AUTOSAR XML (schema 4-2-2)
package /ASW_CORE0
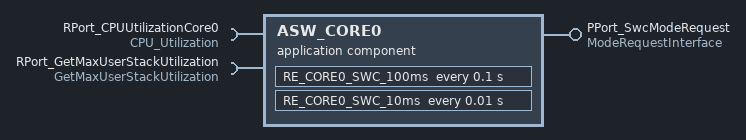
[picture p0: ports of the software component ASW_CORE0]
  application sw component type ASW_CORE0
    require port RPort_CPUUtilizationCore0: required-interface=CPU_Utilization
    provide port PPort_SwcModeRequest: provided-interface=ModeRequestInterface
    require port RPort_GetMaxUserStackUtilization: required-interface=GetMaxUserStackUtilization
    behavior SwcInternalBehavior: data-type-mapping=AppMode_Mapping
      timing event TimingEvent_0: start-on-event=RE_CORE0_SWC_100ms, period=0.1
      asynchronous server call returns event AsynchronousServerCallReturnsEvent_0: start-on-event=RE_CORE0_CPU_Utilization_GetResult, event-source=RE_CORE0_SWC_100ms/AsynchronousServerCallResultPoint_0
      timing event TimingEvent_1: start-on-event=RE_CORE0_SWC_10ms, period=0.01
      4 x runnable:
        RE_CORE0_SWC_100ms: can-be-invoked-concurrently=true, symbol=RE_CORE0_SWC_100ms_func
          asynchronous server call result point AsynchronousServerCallResultPoint_0: asynchronous-server-call-point=AsynchronousServerCallPoint_1
          read-local-variables:
            access ReadLocalVariables_VariableAccess_0
          async call AsynchronousServerCallPoint_1: operation=RPort_CPUUtilizationCore0.CPU_Utilization
          sync call SynchronousServerCallPoint_0: operation=RPort_GetMaxUserStackUtilization.GetMaxUserStackUtilization
        RE_Core0FaultReaction
          data-send-points:
            access DSP_AppMode_0: accessed-variable=PPort_SwcModeRequest.AppMode
        RE_CORE0_CPU_Utilization_GetResult: symbol=RE_CORE0_CPU_Utilization_GetResult_func
          asynchronous server call result point AsynchronousServerCallResultPoint_0
        RE_CORE0_SWC_10ms: symbol=RE_CORE0_SWC_10ms_func
          written-local-variables:
            access WrittenLocalVariables_VariableAccess_0
